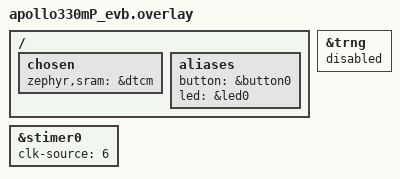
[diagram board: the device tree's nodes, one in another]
/*
 * Copyright (c) 2026, Ambiq Micro Inc. <www.ambiq.com>
 *
 * SPDX-License-Identifier: Apache-2.0
 */

/ {
	/delete-node/ xo48m_xtal;

	chosen {
		zephyr,sram = &dtcm;
	};

	aliases {
		button = &button0;
		led = &led0;
	};
};

&stimer0 {
	clk-source = <6>;
};

&trng {
	status = "disabled";
};
